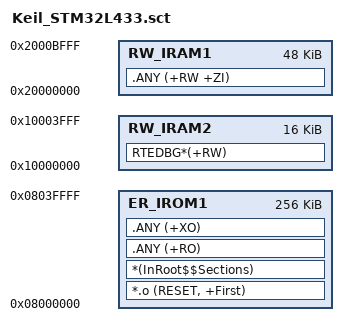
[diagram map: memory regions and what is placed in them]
; *************************************************************
; ***  Scatter-Loading Description File for STM32L433 DEMO  ***
; *************************************************************

LR_IROM1 0x08000000 0x00040000  {    ; load region size_region
  ER_IROM1 0x08000000 0x00040000  {  ; load address = execution address
   *.o (RESET, +First)
   *(InRoot$$Sections)
   .ANY (+RO)
   .ANY (+XO)
  }
  RW_IRAM2 0x10000000 0x00004000  {  ; RW data
   RTEDBG*(+RW)
  }
  RW_IRAM1 0x20000000 0x0000C000  {  ; RW data
   .ANY (+RW +ZI)
  }
}

